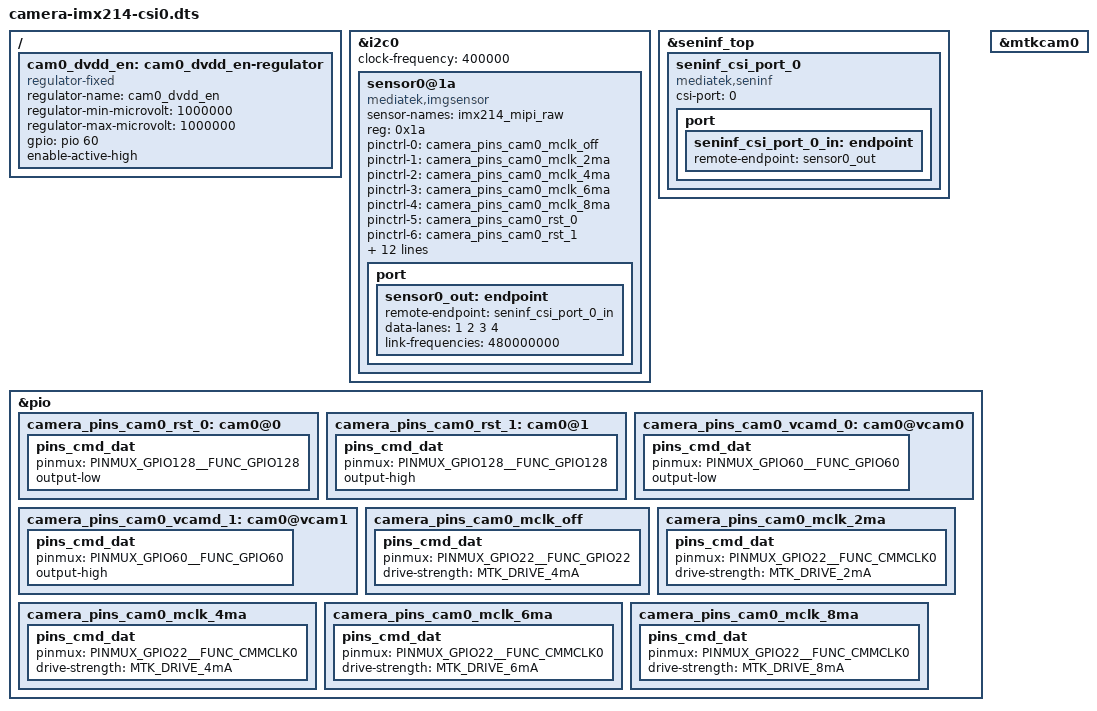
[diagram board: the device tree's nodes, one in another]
// SPDX-License-Identifier: GPL-2.0
/*
 * Copyright (c) 2022 MediaTek Inc.
 *
 */

#include <dt-bindings/clock/mt8195-clk.h>
#include <dt-bindings/gpio/gpio.h>
#include <dt-bindings/pinctrl/mt8195-pinfunc.h>

/dts-v1/;
/plugin/;

#include "isp70.dtsi"
#include "mtk-camera.dtsi"

/ {
	fragment@4 {
		target-path = "/";
		__overlay__ {
			cam0_dvdd_en: cam0_dvdd_en-regulator {
				compatible = "regulator-fixed";
				regulator-name = "cam0_dvdd_en";
				regulator-min-microvolt = <1000000>;
				regulator-max-microvolt = <1000000>;
				gpio = <&pio 60 0>;
				enable-active-high;
			};
		};
	};

	fragment@5 {
		target = <&i2c0>;
		__overlay__ {
			clock-frequency = <400000>;

			sensor0@1a {
				compatible = "mediatek,imgsensor";
				sensor-names = "imx214_mipi_raw";
				reg = <0x1a>;
				status = "okay";

				pinctrl-names = "mclk_off",
						"mclk_2mA",
						"mclk_4mA",
						"mclk_6mA",
						"mclk_8mA",
						"rst_low",
						"rst_high",
						"dvdd_off",
						"dvdd_on";
				pinctrl-0 = <&camera_pins_cam0_mclk_off>;
				pinctrl-1 = <&camera_pins_cam0_mclk_2ma>;
				pinctrl-2 = <&camera_pins_cam0_mclk_4ma>;
				pinctrl-3 = <&camera_pins_cam0_mclk_6ma>;
				pinctrl-4 = <&camera_pins_cam0_mclk_8ma>;
				pinctrl-5 = <&camera_pins_cam0_rst_0>;
				pinctrl-6 = <&camera_pins_cam0_rst_1>;
				pinctrl-7 = <&camera_pins_cam0_vcamd_0>;
				pinctrl-8 = <&camera_pins_cam0_vcamd_1>;
				dovdd-supply = <&mt6359_vcamio_ldo_reg>;
				avdd-supply = <&mt6359_vfe28_ldo_reg>;

				clocks = <&topckgen CLK_TOP_UNIVPLL_192M_D32>,
					<&topckgen CLK_TOP_UNIVPLL_192M_D16>,
					<&topckgen CLK_TOP_CLK26M_D2>,
					<&topckgen CLK_TOP_UNIVPLL_192M_D8>,
					<&topckgen CLK_TOP_UNIVPLL_D6_D16>,
					<&topckgen CLK_TOP_UNIVPLL_192M_D4>,
					<&topckgen CLK_TOP_UNIVPLL_D6_D8>,
					<&topckgen CLK_TOP_CAMTG>;
				clock-names = "6", "12", "13", "24", "26", "48", "52", "mclk";

				port {
					sensor0_out: endpoint {
						remote-endpoint = <&seninf_csi_port_0_in>;
						data-lanes = <1 2 3 4>;
						link-frequencies = /bits/ 64 <480000000>;
					};
				};

			};
		};
	};

	fragment@6 {
		target = <&seninf_top>;
		__overlay__ {
			seninf_csi_port_0: seninf_csi_port_0 {
				compatible = "mediatek,seninf";
				csi-port = "0";
				port {
					seninf_csi_port_0_in: endpoint {
						remote-endpoint = <&sensor0_out>;
					};
				};
			};
		};
	};

	fragment@7 {
		target = <&pio>;
		__overlay__ {
			camera_pins_cam0_rst_0: cam0@0 {
				pins_cmd_dat {
					pinmux = <PINMUX_GPIO128__FUNC_GPIO128>;
					output-low;
				};
			};
			camera_pins_cam0_rst_1: cam0@1 {
				pins_cmd_dat {
					pinmux = <PINMUX_GPIO128__FUNC_GPIO128>;
					output-high;
				};
			};
			camera_pins_cam0_vcamd_0: cam0@vcam0 {
				pins_cmd_dat {
					pinmux = <PINMUX_GPIO60__FUNC_GPIO60>;
					output-low;
				};
			};
			camera_pins_cam0_vcamd_1: cam0@vcam1 {
				pins_cmd_dat {
					pinmux = <PINMUX_GPIO60__FUNC_GPIO60>;
					output-high;
				};
			};
			camera_pins_cam0_mclk_off: camera_pins_cam0_mclk_off {
				pins_cmd_dat {
					pinmux = <PINMUX_GPIO22__FUNC_GPIO22>;
					drive-strength = <MTK_DRIVE_4mA>;
				};
			};
			camera_pins_cam0_mclk_2ma: camera_pins_cam0_mclk_2ma {
				pins_cmd_dat {
					pinmux = <PINMUX_GPIO22__FUNC_CMMCLK0>;
					drive-strength = <MTK_DRIVE_2mA>;
				};
			};
			camera_pins_cam0_mclk_4ma: camera_pins_cam0_mclk_4ma {
				pins_cmd_dat {
					pinmux = <PINMUX_GPIO22__FUNC_CMMCLK0>;
					drive-strength = <MTK_DRIVE_4mA>;
				};
			};
			camera_pins_cam0_mclk_6ma: camera_pins_cam0_mclk_6ma {
				pins_cmd_dat {
					pinmux = <PINMUX_GPIO22__FUNC_CMMCLK0>;
					drive-strength = <MTK_DRIVE_6mA>;
				};
			};
			camera_pins_cam0_mclk_8ma: camera_pins_cam0_mclk_8ma {
				pins_cmd_dat {
					pinmux = <PINMUX_GPIO22__FUNC_CMMCLK0>;
					drive-strength = <MTK_DRIVE_8mA>;
				};
			};
		};
	};

	fragment@8 {
		target = <&mtkcam0>;
		__overlay__ {
			status = "okay";
		};
	};
};
